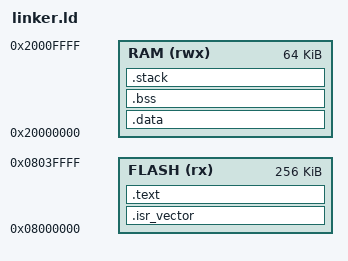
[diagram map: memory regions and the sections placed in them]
/* 链接器脚本 for ARM Cortex-M3 */
MEMORY
{
    FLASH (rx) : ORIGIN = 0x08000000, LENGTH = 256K
    RAM (rwx)  : ORIGIN = 0x20000000, LENGTH = 64K
}

/* 栈大小定义 */
_stack_size = 0x1000;

/* 入口点 */
ENTRY(main)

SECTIONS
{
    /* 向量表 */
    .isr_vector :
    {
        . = ALIGN(4);
        KEEP(*(.isr_vector))
        . = ALIGN(4);
    } > FLASH

    /* 代码段 */
    .text :
    {
        . = ALIGN(4);
        *(.text)
        *(.text*)
        *(.rodata)
        *(.rodata*)
        . = ALIGN(4);
    } > FLASH

    /* 数据初始化值 */
    _sidata = .;
    
    .data : AT ( _sidata )
    {
        . = ALIGN(4);
        _sdata = .;
        *(.data)
        *(.data*)
        . = ALIGN(4);
        _edata = .;
    } > RAM

    /* 未初始化数据 (BSS) */
    .bss :
    {
        . = ALIGN(4);
        _sbss = .;
        *(.bss)
        *(.bss*)
        *(COMMON)
        . = ALIGN(4);
        _ebss = .;
    } > RAM

    /* 栈 */
    .stack (NOLOAD) :
    {
        . = ALIGN(8);
        _sstack = .;
        . = . + _stack_size;
        . = ALIGN(8);
        _estack = .;
    } > RAM

    /* 调试信息 */
    /DISCARD/ :
    {
        *(.comment)
        *(.ARM.attributes)
    }
}
